# VPE_PRM register map
Vendor: Texas Instruments
Peripheral module from a debugger description file (folder TDA2Px).
Registers are 32-bit, access per field, reset 0x30003 unless marked. A register's access mark holds for its fields unless they carry their own. Offsets are as the file gives them; lines under a group give offsets from that group; [hi:lo] are bit positions; {n}, {i} and the like mark numbered series; 'fields as' and 'values as' point back to an identical list; <NAME> marks a mode.

## VPE_PRM
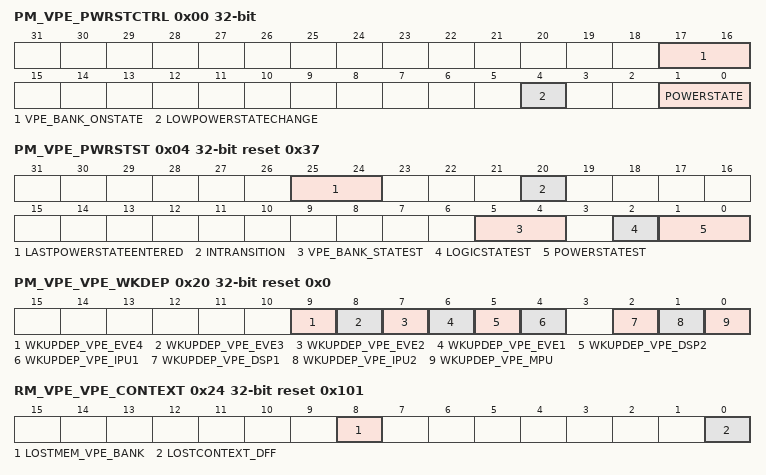
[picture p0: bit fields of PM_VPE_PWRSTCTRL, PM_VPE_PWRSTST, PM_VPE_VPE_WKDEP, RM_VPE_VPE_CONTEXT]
0x00 PM_VPE_PWRSTCTRL — This register controls the VPE power state to reach upon a domain sleep transition
  [17:16] VPE_BANK_ONSTATE ro — DSP_L1 state when domain is ON.
    3=MEM_ON (Memory bank is on when the domain is ON.)
  [4] LOWPOWERSTATECHANGE rw — Power state change request when domain has already performed a sleep transition. Allows going into deeper low power state without waking up the power domain.
    0=DIS (Do not request a low power state change.); 1=EN (Request a low power state change. This bit is automatically cleared when the power state is effectively changed or when power state is ON.)
  [1:0] POWERSTATE rw — Power state control
    0=OFF (OFF state); 1=RET (Reserved); 2=INACT (Reserved); 3=ON (ON State)
0x04 PM_VPE_PWRSTST reset 0x37 — This register provides a status on the VPE domain current power state. [warm reset insensitive]
  [25:24] LASTPOWERSTATEENTERED rw — Last low power state entered. Set to 0x3 upon write of the same only. This register is intended for debug purpose only.
    0=OFF (Power domain was previously OFF); 1=RET (Reserved); 2=INACTIVE (Reserved); 3=ON (Power domain was previously ON-ACTIVE)
  [20] INTRANSITION ro — Domain transition status
    0=NO (No on-going transition on power domain); 1=ONGOING (Power domain transition is in progress.)
  [5:4] VPE_BANK_STATEST ro — VPE_BANK memory state status
    0=MEM_OFF (Memory is OFF); 1=MEM_RET (Reserved); 3=MEM_ON (Memory is ON)
  [2] LOGICSTATEST ro — Logic state status
    0=OFF (Reserved); 1=ON (Logic in domain is ON)
  [1:0] POWERSTATEST ro — Current power state status
    0=OFF (Power domain is OFF); 1=RET (Reserved); 2=INACTIVE (Reserved); 3=ON (Power domain is ON-ACTIVE)
0x20 PM_VPE_VPE_WKDEP reset 0x0 — This register controls wakeup dependency based on VPE service requests.
  [9] WKUPDEP_VPE_EVE4 rw — Wakeup dependency from VPE module (Swakeup signal) towards EVE4 + L3_MAIN1 + L4PER1 + L4PER2 + L4PER3 domainsEVE4 is not supported in this family of devices.
    0=DISABLED (Dependency is disabled); 1=ENABLED (Dependency is enabled)
  [8] WKUPDEP_VPE_EVE3 rw — Wakeup dependency from VPE module (Swakeup signal) towards EVE3 + L3_MAIN1 + L4PER1 + L4PER2 + L4PER3 domainsEVE3 is not supported in this family of devices.
    values as WKUPDEP_VPE_EVE4
  [7] WKUPDEP_VPE_EVE2 rw — Wakeup dependency from VPE module (Swakeup signal) towards EVE2 + L3_MAIN1 + L4PER1 + L4PER2 + L4PER3 domains
    values as WKUPDEP_VPE_EVE4
  [6] WKUPDEP_VPE_EVE1 rw — Wakeup dependency from VPE module ( Swakeup signal) towards EVE1 + L3_MAIN1 + L4PER1 + L4PER2 + L4PER3 domains
    values as WKUPDEP_VPE_EVE4
  [5] WKUPDEP_VPE_DSP2 rw — Wakeup dependency from VPE module (Swakeup signal) towards DSP2 + L3_MAIN1 + L4PER1 + L4PER2 + L4PER3 domains
    values as WKUPDEP_VPE_EVE4
  [4] WKUPDEP_VPE_IPU1 rw — Wakeup dependency from VPE module (Swakeup signal) towards IPU1 + L3_MAIN1 + L4PER1 + L4PER2 + L4PER3 domains
    values as WKUPDEP_VPE_EVE4
  [2] WKUPDEP_VPE_DSP1 rw — Wakeup dependency from VPE module (Swakeup signal) towards DSP1 + L3_MAIN1 + L4PER1 + L4PER2 + L4PER3 domains
    values as WKUPDEP_VPE_EVE4
  [1] WKUPDEP_VPE_IPU2 rw — Wakeup dependency from VPE module ( Swakeup signal) towards IPU2 + L3_MAIN1 + L4PER1 + L4PER2 + L4PER3 domains
    0=Dependency_is_disabled; 1=Dependency_is_enabled
  [0] WKUPDEP_VPE_MPU rw — Wakeup dependency from VPE module (Swakeup signal) towards MPU + L3_MAIN1 + L4PER1 + L4PER2 + L4PER3 domains
    values as WKUPDEP_VPE_EVE4
0x24 RM_VPE_VPE_CONTEXT reset 0x101 — This register contains dedicated VPE context statuses. [warm reset insensitive]
  [8] LOSTMEM_VPE_BANK rw — Specify if memory-based context in VPE memory bank has been lost due to a previous power transition or other reset source.
    0=MAINTAINED (Context has been maintained); 1=LOST (Context has been lost)
  [0] LOSTCONTEXT_DFF rw — Specify if DFF-based context has been lost due to a previous power transition or other reset source. (set upon assertion of VPE_RST signal)
    values as LOSTMEM_VPE_BANK
